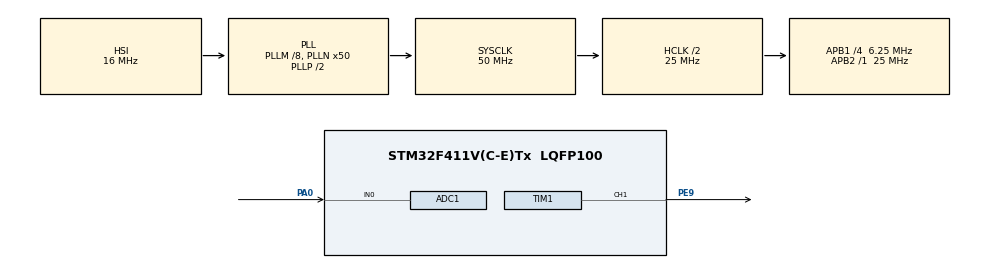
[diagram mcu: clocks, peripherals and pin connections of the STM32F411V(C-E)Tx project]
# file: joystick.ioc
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ADC1.Channel-0\#ChannelRegularConversion=ADC_CHANNEL_0
ADC1.NbrOfConversionFlag=1
ADC1.Rank-0\#ChannelRegularConversion=1
ADC1.SamplingTime-0\#ChannelRegularConversion=ADC_SAMPLETIME_3CYCLES
ADC1.master=1
Mcu.Family=STM32F4
Mcu.Name=STM32F411V(C-E)Tx
Mcu.Package=LQFP100
NVIC.PriorityGroup=NVIC_PRIORITYGROUP_0
PA0-WKUP.Signal=ADCx_IN0
PE9.Signal=S_TIM1_CH1
ProjectManager.HeapSize=0x200
ProjectManager.StackSize=0x400
ProjectManager.TargetToolchain=STM32CubeIDE
RCC.48MHZClocksFreq_Value=12500000
RCC.AHBCLKDivider=RCC_SYSCLK_DIV2
RCC.AHBFreq_Value=25000000
RCC.APB1CLKDivider=RCC_HCLK_DIV4
RCC.APB1Freq_Value=6250000
RCC.APB1TimFreq_Value=12500000
RCC.APB2Freq_Value=25000000
RCC.APB2TimFreq_Value=25000000
RCC.CortexFreq_Value=25000000
RCC.HCLKFreq_Value=25000000
RCC.HSE_VALUE=8000000
RCC.HSI_VALUE=16000000
RCC.PLLI2SM=5
RCC.PLLI2SN=200
RCC.PLLM=8
RCC.PLLN=50
RCC.PLLQ=8
RCC.SYSCLKFreq_VALUE=50000000
RCC.SYSCLKSource=RCC_SYSCLKSOURCE_PLLCLK
RCC.VCOOutputFreq_Value=100000000
SH.ADCx_IN0.0=ADC1_IN0,IN0
SH.S_TIM1_CH1.0=TIM1_CH1,PWM Generation1 CH1
TIM1.Channel-PWM\ Generation1\ CH1=TIM_CHANNEL_1
TIM1.Period=19999
TIM1.Prescaler=24
VP_TIM1_VS_ClockSourceINT.Mode=Internal
board=STM32F411E-DISCO

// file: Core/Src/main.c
/* USER CODE BEGIN Header */
/**
  ******************************************************************************
  * @file           : main.c
  * @brief          : Main program body
  ******************************************************************************
  * @attention
  *
  * Copyright (c) 2026 STMicroelectronics.
  * All rights reserved.
  *
  * This software is licensed under terms that can be found in the LICENSE file
  * in the root directory of this software component.
  * If no LICENSE file comes with this software, it is provided AS-IS.
  *
  ******************************************************************************
  */
/* USER CODE END Header */
#include "main.h"

ADC_HandleTypeDef hadc1;

TIM_HandleTypeDef htim1;

void SystemClock_Config(void);
static void MX_GPIO_Init(void);
static void MX_ADC1_Init(void);
static void MX_TIM1_Init(void);

int main(void)
{

  /* MCU Configuration--------------------------------------------------------*/

  /* Reset of all peripherals, Initializes the Flash interface and the Systick. */
  HAL_Init();

  /* Configure the system clock */
  SystemClock_Config();

  /* Initialize all configured peripherals */
  MX_GPIO_Init();
  MX_ADC1_Init();
  MX_TIM1_Init();
  /* USER CODE BEGIN 2 */
  // Arrancamos el PWM del Timer 1 Canal 1 (Pin PA8)
  HAL_TIM_PWM_Start(&htim1, TIM_CHANNEL_1);
  /* USER CODE END 2 */

  /* Infinite loop */
  /* USER CODE BEGIN WHILE */
  uint32_t adc_joystick = 0;
  uint32_t pwm_servo = 1500; // Empezamos en la posición central (90°)

  while (1)
  {
      // 1. Iniciar la conversión del ADC de forma manual
      HAL_ADC_Start(&hadc1);

      // 2. Esperar a que la lectura termine (máximo 10ms de espera)
      if (HAL_ADC_PollForConversion(&hadc1, 10) == HAL_OK)
      {
          // 3. Guardar el valor leído del joystick (va de 0 a 4095)
          adc_joystick = HAL_ADC_GetValue(&hadc1);
      }

      // Detener el ADC hasta el próximo ciclo
      HAL_ADC_Stop(&hadc1);

      // 4. MAPEO MATEMÁTICO (Convertir escala 0-4095 a escala 500-2500)
      // Usamos una ecuación lineal simple para evitar números flotantes (float) que ralentizan la STM32:
      pwm_servo = 500 + ((adc_joystick * 2000) / 4095);

      // 5. Aplicar el valor calculado al registro del canal PWM
      __HAL_TIM_SET_COMPARE(&htim1, TIM_CHANNEL_1, pwm_servo);

      // Pequeño retardo de 20ms para dar estabilidad al servo y que no tiemble
      HAL_Delay(20);

    /* USER CODE END WHILE */

  }
}

void SystemClock_Config(void)
{
  RCC_OscInitTypeDef RCC_OscInitStruct = {0};
  RCC_ClkInitTypeDef RCC_ClkInitStruct = {0};

  /** Configure the main internal regulator output voltage
  */
  __HAL_RCC_PWR_CLK_ENABLE();
  __HAL_PWR_VOLTAGESCALING_CONFIG(PWR_REGULATOR_VOLTAGE_SCALE1);

  /** Initializes the RCC Oscillators according to the specified parameters
  * in the RCC_OscInitTypeDef structure.
  */
  RCC_OscInitStruct.OscillatorType = RCC_OSCILLATORTYPE_HSI;
  RCC_OscInitStruct.HSIState = RCC_HSI_ON;
  RCC_OscInitStruct.HSICalibrationValue = RCC_HSICALIBRATION_DEFAULT;
  RCC_OscInitStruct.PLL.PLLState = RCC_PLL_ON;
  RCC_OscInitStruct.PLL.PLLSource = RCC_PLLSOURCE_HSI;
  RCC_OscInitStruct.PLL.PLLM = 8;
  RCC_OscInitStruct.PLL.PLLN = 50;
  RCC_OscInitStruct.PLL.PLLP = RCC_PLLP_DIV2;
  RCC_OscInitStruct.PLL.PLLQ = 8;
  if (HAL_RCC_OscConfig(&RCC_OscInitStruct) != HAL_OK)
  {
    Error_Handler();
  }

  /** Initializes the CPU, AHB and APB buses clocks
  */
  RCC_ClkInitStruct.ClockType = RCC_CLOCKTYPE_HCLK|RCC_CLOCKTYPE_SYSCLK
                              |RCC_CLOCKTYPE_PCLK1|RCC_CLOCKTYPE_PCLK2;
  RCC_ClkInitStruct.SYSCLKSource = RCC_SYSCLKSOURCE_PLLCLK;
  RCC_ClkInitStruct.AHBCLKDivider = RCC_SYSCLK_DIV2;
  RCC_ClkInitStruct.APB1CLKDivider = RCC_HCLK_DIV4;
  RCC_ClkInitStruct.APB2CLKDivider = RCC_HCLK_DIV1;

  if (HAL_RCC_ClockConfig(&RCC_ClkInitStruct, FLASH_LATENCY_0) != HAL_OK)
  {
    Error_Handler();
  }
}

static void MX_ADC1_Init(void)
{

  ADC_ChannelConfTypeDef sConfig = {0};

  /** Configure the global features of the ADC (Clock, Resolution, Data Alignment and number of conversion)
  */
  hadc1.Instance = ADC1;
  hadc1.Init.ClockPrescaler = ADC_CLOCK_SYNC_PCLK_DIV2;
  hadc1.Init.Resolution = ADC_RESOLUTION_12B;
  hadc1.Init.ScanConvMode = DISABLE;
  hadc1.Init.ContinuousConvMode = DISABLE;
  hadc1.Init.DiscontinuousConvMode = DISABLE;
  hadc1.Init.ExternalTrigConvEdge = ADC_EXTERNALTRIGCONVEDGE_NONE;
  hadc1.Init.ExternalTrigConv = ADC_SOFTWARE_START;
  hadc1.Init.DataAlign = ADC_DATAALIGN_RIGHT;
  hadc1.Init.NbrOfConversion = 1;
  hadc1.Init.DMAContinuousRequests = DISABLE;
  hadc1.Init.EOCSelection = ADC_EOC_SINGLE_CONV;
  if (HAL_ADC_Init(&hadc1) != HAL_OK)
  {
    Error_Handler();
  }

  /** Configure for the selected ADC regular channel its corresponding rank in the sequencer and its sample time.
  */
  sConfig.Channel = ADC_CHANNEL_0;
  sConfig.Rank = 1;
  sConfig.SamplingTime = ADC_SAMPLETIME_3CYCLES;
  if (HAL_ADC_ConfigChannel(&hadc1, &sConfig) != HAL_OK)
  {
    Error_Handler();
  }

}

static void MX_TIM1_Init(void)
{

  TIM_ClockConfigTypeDef sClockSourceConfig = {0};
  TIM_MasterConfigTypeDef sMasterConfig = {0};
  TIM_OC_InitTypeDef sConfigOC = {0};
  TIM_BreakDeadTimeConfigTypeDef sBreakDeadTimeConfig = {0};

  htim1.Instance = TIM1;
  htim1.Init.Prescaler = 24;
  htim1.Init.CounterMode = TIM_COUNTERMODE_UP;
  htim1.Init.Period = 19999;
  htim1.Init.ClockDivision = TIM_CLOCKDIVISION_DIV1;
  htim1.Init.RepetitionCounter = 0;
  htim1.Init.AutoReloadPreload = TIM_AUTORELOAD_PRELOAD_DISABLE;
  if (HAL_TIM_Base_Init(&htim1) != HAL_OK)
  {
    Error_Handler();
  }
  sClockSourceConfig.ClockSource = TIM_CLOCKSOURCE_INTERNAL;
  if (HAL_TIM_ConfigClockSource(&htim1, &sClockSourceConfig) != HAL_OK)
  {
    Error_Handler();
  }
  if (HAL_TIM_PWM_Init(&htim1) != HAL_OK)
  {
    Error_Handler();
  }
  sMasterConfig.MasterOutputTrigger = TIM_TRGO_RESET;
  sMasterConfig.MasterSlaveMode = TIM_MASTERSLAVEMODE_DISABLE;
  if (HAL_TIMEx_MasterConfigSynchronization(&htim1, &sMasterConfig) != HAL_OK)
  {
    Error_Handler();
  }
  sConfigOC.OCMode = TIM_OCMODE_PWM1;
  sConfigOC.Pulse = 0;
  sConfigOC.OCPolarity = TIM_OCPOLARITY_HIGH;
  sConfigOC.OCNPolarity = TIM_OCNPOLARITY_HIGH;
  sConfigOC.OCFastMode = TIM_OCFAST_DISABLE;
  sConfigOC.OCIdleState = TIM_OCIDLESTATE_RESET;
  sConfigOC.OCNIdleState = TIM_OCNIDLESTATE_RESET;
  if (HAL_TIM_PWM_ConfigChannel(&htim1, &sConfigOC, TIM_CHANNEL_1) != HAL_OK)
  {
    Error_Handler();
  }
  sBreakDeadTimeConfig.OffStateRunMode = TIM_OSSR_DISABLE;
  sBreakDeadTimeConfig.OffStateIDLEMode = TIM_OSSI_DISABLE;
  sBreakDeadTimeConfig.LockLevel = TIM_LOCKLEVEL_OFF;
  sBreakDeadTimeConfig.DeadTime = 0;
  sBreakDeadTimeConfig.BreakState = TIM_BREAK_DISABLE;
  sBreakDeadTimeConfig.BreakPolarity = TIM_BREAKPOLARITY_HIGH;
  sBreakDeadTimeConfig.AutomaticOutput = TIM_AUTOMATICOUTPUT_DISABLE;
  if (HAL_TIMEx_ConfigBreakDeadTime(&htim1, &sBreakDeadTimeConfig) != HAL_OK)
  {
    Error_Handler();
  }
  HAL_TIM_MspPostInit(&htim1);

}

static void MX_GPIO_Init(void)
{

  /* GPIO Ports Clock Enable */
  __HAL_RCC_GPIOA_CLK_ENABLE();
  __HAL_RCC_GPIOE_CLK_ENABLE();

}

void Error_Handler(void)
{
  __disable_irq();
  while (1)
  {
  }
}
